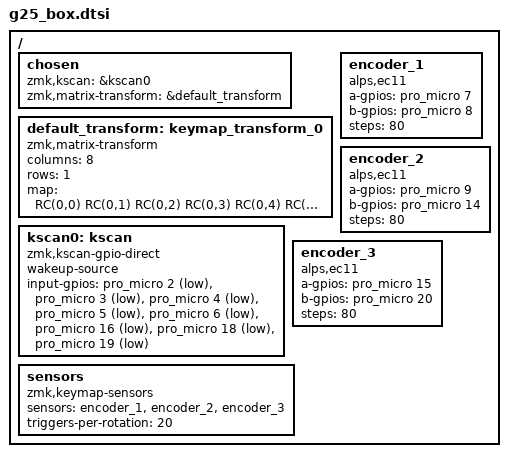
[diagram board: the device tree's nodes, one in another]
/*
 * Copyright (c) 2026
 * SPDX-License-Identifier: MIT
 */

#include <dt-bindings/zmk/matrix_transform.h>

/ {
    chosen {
        zmk,kscan = &kscan0;
        zmk,matrix-transform = &default_transform;
    };

    default_transform: keymap_transform_0 {
        compatible = "zmk,matrix-transform";
        columns = <8>;
        rows = <1>;

        map = <
    RC(0,0) RC(0,1) RC(0,2) RC(0,3) RC(0,4) RC(0,5) RC(0,6) RC(0,7)
        >;
    };

    kscan0: kscan {
        compatible = "zmk,kscan-gpio-direct";
        wakeup-source;

        input-gpios
            = <&pro_micro 2 (GPIO_ACTIVE_LOW | GPIO_PULL_UP)>
            , <&pro_micro 3 (GPIO_ACTIVE_LOW | GPIO_PULL_UP)>
            , <&pro_micro 4 (GPIO_ACTIVE_LOW | GPIO_PULL_UP)>
            , <&pro_micro 5 (GPIO_ACTIVE_LOW | GPIO_PULL_UP)>
            , <&pro_micro 6 (GPIO_ACTIVE_LOW | GPIO_PULL_UP)>
            , <&pro_micro 16 (GPIO_ACTIVE_LOW | GPIO_PULL_UP)>
            , <&pro_micro 18 (GPIO_ACTIVE_LOW | GPIO_PULL_UP)>
            , <&pro_micro 19 (GPIO_ACTIVE_LOW | GPIO_PULL_UP)>
            ;
    };

    encoder_1: encoder_1 {
        compatible = "alps,ec11";
        a-gpios = <&pro_micro 7 (GPIO_ACTIVE_HIGH | GPIO_PULL_UP)>;
        b-gpios = <&pro_micro 8 (GPIO_ACTIVE_HIGH | GPIO_PULL_UP)>;
        steps = <80>;
    };

    encoder_2: encoder_2 {
        compatible = "alps,ec11";
        a-gpios = <&pro_micro 9 (GPIO_ACTIVE_HIGH | GPIO_PULL_UP)>;
        b-gpios = <&pro_micro 14 (GPIO_ACTIVE_HIGH | GPIO_PULL_UP)>;
        steps = <80>;
    };

    encoder_3: encoder_3 {
        compatible = "alps,ec11";
        a-gpios = <&pro_micro 15 (GPIO_ACTIVE_HIGH | GPIO_PULL_UP)>;
        b-gpios = <&pro_micro 20 (GPIO_ACTIVE_HIGH | GPIO_PULL_UP)>;
        steps = <80>;
    };

    sensors: sensors {
        compatible = "zmk,keymap-sensors";
        sensors = <&encoder_1 &encoder_2 &encoder_3>;
        triggers-per-rotation = <20>;
    };
};
